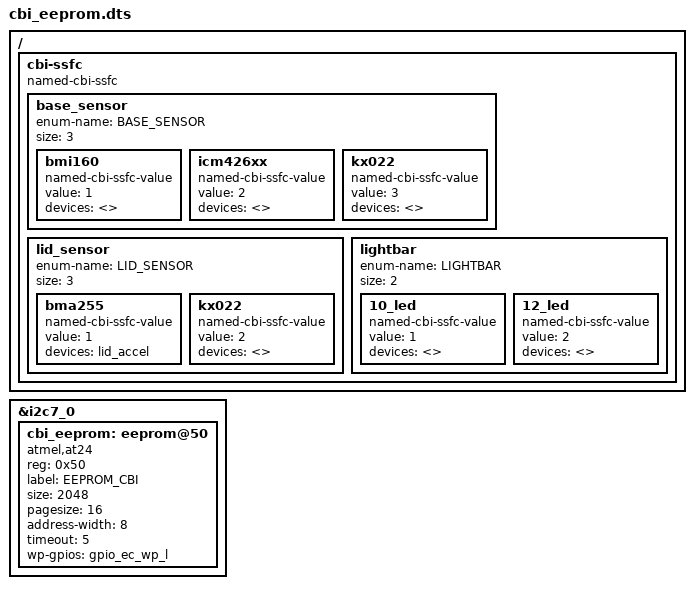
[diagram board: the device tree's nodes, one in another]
/* Copyright 2021 The Chromium OS Authors. All rights reserved.
 * Use of this source code is governed by a BSD-style license that can be
 * found in the LICENSE file.
 */

&i2c7_0 {
	cbi_eeprom: eeprom@50 {
		compatible = "atmel,at24";
		reg = <0x50>;
		label = "EEPROM_CBI";
		size = <2048>;
		pagesize = <16>;
		address-width = <8>;
		timeout = <5>;
		wp-gpios = <&gpio_ec_wp_l>;
	};
};

/ {
	cbi-ssfc {
		compatible = "named-cbi-ssfc";

		base_sensor {
			enum-name = "BASE_SENSOR";
			size = <3>;
			bmi160 {
				compatible = "named-cbi-ssfc-value";
				status = "okay";

				value = <1>;
				devices = <>;
			};
			icm426xx {
				compatible = "named-cbi-ssfc-value";
				status = "okay";

				value = <2>;
				devices = <>;
			};
			kx022 {
				compatible = "named-cbi-ssfc-value";
				status = "okay";

				value = <3>;
				devices = <>;
			};
		};
		lid_sensor {
			enum-name = "LID_SENSOR";
			size = <3>;
			bma255 {
				compatible = "named-cbi-ssfc-value";
				status = "okay";

				value = <1>;
				devices = <&lid_accel>;
			};
			kx022 {
				compatible = "named-cbi-ssfc-value";
				status = "okay";

				value = <2>;
				devices = <>;
			};
		};
		lightbar {
			enum-name = "LIGHTBAR";
			size = <2>;
			10_led {
				compatible = "named-cbi-ssfc-value";
				status = "okay";

				value = <1>;
				devices = <>;
			};
			12_led {
				compatible = "named-cbi-ssfc-value";
				status = "okay";

				value = <2>;
				devices = <>;
			};
		};
	};
};
